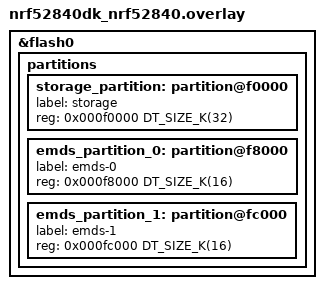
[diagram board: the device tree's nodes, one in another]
/delete-node/ &storage_partition;

&flash0 {
	partitions {
		storage_partition: partition@f0000 {
			label = "storage";
			reg = <0x000f0000 DT_SIZE_K(32)>;
		};

		emds_partition_0: partition@f8000 {
			label = "emds-0";
			reg = <0x000f8000 DT_SIZE_K(16)>;
		};

		emds_partition_1: partition@fc000 {
			label = "emds-1";
			reg = <0x000fc000 DT_SIZE_K(16)>;
		};
	};
};
